# AXI2VBUS_MASTER register map
Vendor: Texas Instruments
Peripheral module from a debugger description file (folder 66AK2G0x_66AK2G1x).
Registers are 32-bit, read-only, reset values left out (the file's numbers can be read two ways) unless marked. A register's access mark holds for its fields unless they carry their own. Offsets are as the file gives them; lines under a group give offsets from that group; [hi:lo] are bit positions; {n}, {i} and the like mark numbered series; 'fields as' and 'values as' point back to an identical list; <NAME> marks a mode.

## AXI2VBUS_MASTER
0x00 AXI2VBUS_PID
  [31:0] PID — TI internal data. Identifies revision of peripheral.
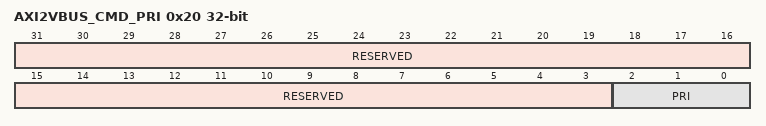
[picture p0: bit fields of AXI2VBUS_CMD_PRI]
0x20 AXI2VBUS_CMD_PRI access per field
  [31:3] RESERVED ro — Read returns reset value
  [2:0] PRI rw — Set priority of the command. Default is 7h which means the lowest VBUSM priority
0x30 AXI2VBUS_CPU0_END rw
  [31:0] ENDIAN — CPU Endian mode configuration and status register
